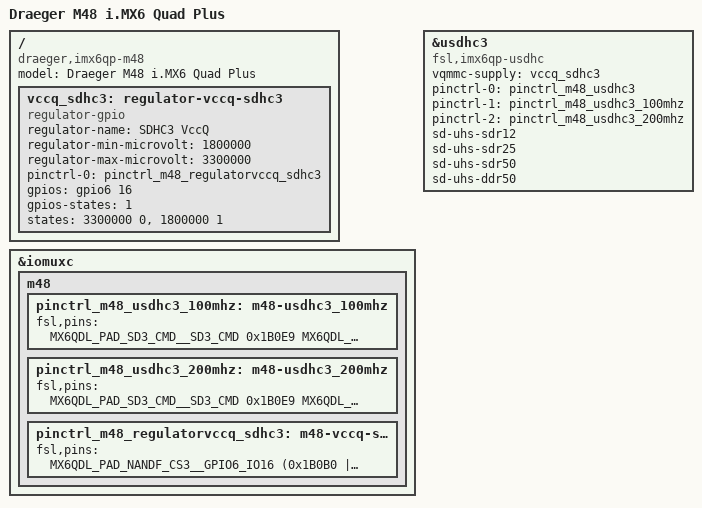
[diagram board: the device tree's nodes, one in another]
// SPDX-License-Identifier: GPL-2.0+
/*
 *  (C) Copyright 2020 Draeger and Licensors, info@draeger.com
 *
 *  Device Tree file for Drager M48 Board
 */

/dts-v1/;

#include "imx6q.dtsi"
/* PAD config disabled in imx6qdl-draeger-m48.dtsi by setting value to 0x80000000
 * PAD configuration register must not be 0, so it is set to 0xfff
 */
#define MX6QDL_PAD_CTL_GRP_DDR_TYPE_RGMII        0x790 0xfff 0x000 0x000C0000 0x0
#define MX6QDL_PAD_CTL_GRP_RGMII_TERM            0x7ac 0xfff 0x000 0x00000200 0x0
#define IMX_PAD_SION	                         0x40000000	/* set SION */

#include "imx6qdl-draeger-m48.dtsi"
#include "imx6qdl-draeger-m48-u-boot.dtsi"

/ {
	model = "Draeger M48 i.MX6 Quad Plus";
	compatible = "draeger,imx6qp-m48", "fsl,imx6qp";

	vccq_sdhc3: regulator-vccq-sdhc3 {
		compatible = "regulator-gpio";
		regulator-name = "SDHC3 VccQ";
		regulator-min-microvolt = <1800000>;
		regulator-max-microvolt = <3300000>;
		pinctrl-names = "default";
		pinctrl-0 = <&pinctrl_m48_regulatorvccq_sdhc3>;
		gpios = <&gpio6 16 GPIO_ACTIVE_HIGH>;
		gpios-states = <1>;
		states = <3300000 0>, <1800000 1>;
	};
};

&iomuxc {
	m48 {
		pinctrl_m48_usdhc3_100mhz: m48-usdhc3_100mhz {
			fsl,pins = <
				MX6QDL_PAD_SD3_CMD__SD3_CMD    0x1B0E9
				MX6QDL_PAD_SD3_CLK__SD3_CLK    0x1B0E9
				MX6QDL_PAD_SD3_DAT0__SD3_DATA0 0x1B0E9
				MX6QDL_PAD_SD3_DAT1__SD3_DATA1 0x1B0E9
				MX6QDL_PAD_SD3_DAT2__SD3_DATA2 0x1B0E9
				MX6QDL_PAD_SD3_DAT3__SD3_DATA3 0x1B0E9
			>;
		};
		pinctrl_m48_usdhc3_200mhz: m48-usdhc3_200mhz {
			fsl,pins = <
				MX6QDL_PAD_SD3_CMD__SD3_CMD    0x1B0E9
				MX6QDL_PAD_SD3_CLK__SD3_CLK    0x1B0E9
				MX6QDL_PAD_SD3_DAT0__SD3_DATA0 0x1B0E9
				MX6QDL_PAD_SD3_DAT1__SD3_DATA1 0x1B0E9
				MX6QDL_PAD_SD3_DAT2__SD3_DATA2 0x1B0E9
				MX6QDL_PAD_SD3_DAT3__SD3_DATA3 0x1B0E9
			>;
		};

		pinctrl_m48_regulatorvccq_sdhc3: m48-vccq-sdhc3 {
			fsl,pins = <MX6QDL_PAD_NANDF_CS3__GPIO6_IO16 (0x1B0B0 | IMX_PAD_SION)>;
		};
	};
};

&usdhc3 {
	compatible = "fsl,imx6qp-usdhc";
	vqmmc-supply = <&vccq_sdhc3>;
	pinctrl-names = "default", "state_100mhz", "state_200mhz";
	pinctrl-0 = <&pinctrl_m48_usdhc3>;
	pinctrl-1 = <&pinctrl_m48_usdhc3_100mhz>;
	pinctrl-2 = <&pinctrl_m48_usdhc3_200mhz>;
	sd-uhs-sdr12;
	sd-uhs-sdr25;
	sd-uhs-sdr50;
	sd-uhs-ddr50;
};
